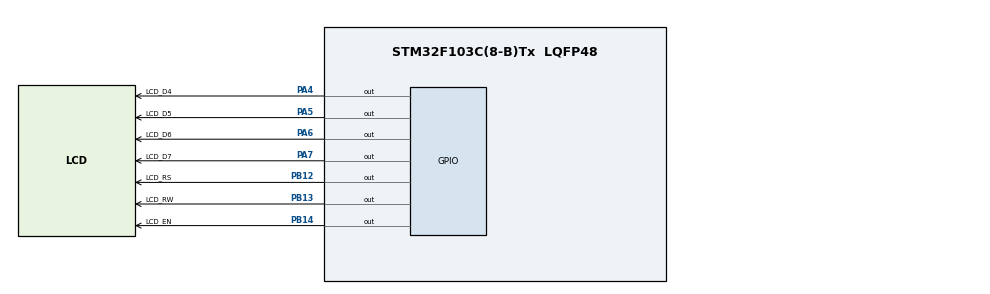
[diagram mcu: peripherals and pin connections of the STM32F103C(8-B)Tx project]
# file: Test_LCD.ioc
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Mcu.Family=STM32F1
PB14.GPIO_Label=LCD_EN
PA6.GPIO_Label=LCD_D6
PB13.GPIO_Label=LCD_RW
PB13.Signal=GPIO_Output
ProjectManager.StackSize=0x400
PA13.Signal=SYS_JTMS-SWDIO
ProjectManager.TargetToolchain=MDK-ARM V5
PB14.Signal=GPIO_Output
PA5.Signal=GPIO_Output
board=custom
PB12.GPIO_Label=LCD_RS
RCC.APB2Freq_Value=8000000
PA14.Mode=Serial_Wire
PA13.Mode=Serial_Wire
Mcu.Name=STM32F103C(8-B)Tx
PA4.Signal=GPIO_Output
Mcu.Package=LQFP48
PA6.Signal=GPIO_Output
PA7.GPIO_Label=LCD_D7
PA5.GPIO_Label=LCD_D5
PA14.Signal=SYS_JTCK-SWCLK
ProjectManager.HeapSize=0x200
NVIC.PriorityGroup=NVIC_PRIORITYGROUP_4
RCC.APB1Freq_Value=8000000
PA4.GPIO_Label=LCD_D4
PB12.Signal=GPIO_Output
PA7.Signal=GPIO_Output

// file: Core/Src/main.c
/* USER CODE BEGIN Header */
/**
  ******************************************************************************
  * @file           : main.c
  * @brief          : Main program body
  ******************************************************************************
  * @attention
  *
  * <h2><center>&copy; Copyright (c) 2021 STMicroelectronics.
  * All rights reserved.</center></h2>
  *
  * This software component is licensed by ST under BSD 3-Clause license,
  * the "License"; You may not use this file except in compliance with the
  * License. You may obtain a copy of the License at:
  *                        opensource.org/licenses/BSD-3-Clause
  *
  ******************************************************************************
  */
/* USER CODE END Header */
#include "main.h"

/* USER CODE BEGIN Includes */
#include "lcd.h"
/* USER CODE END Includes */

void SystemClock_Config(void);
static void MX_GPIO_Init(void);

int main(void)
{

  /* MCU Configuration--------------------------------------------------------*/

  /* Reset of all peripherals, Initializes the Flash interface and the Systick. */
  HAL_Init();

  /* Configure the system clock */
  SystemClock_Config();

  /* Initialize all configured peripherals */
  MX_GPIO_Init();

  /* Infinite loop */
  /* USER CODE BEGIN WHILE */
	Lcd_PortType ports[] = { LCD_D4_GPIO_Port,LCD_D5_GPIO_Port,LCD_D6_GPIO_Port,LCD_D7_GPIO_Port};
  Lcd_PinType pins[] = {LCD_D4_Pin,LCD_D5_Pin,LCD_D6_Pin,LCD_D7_Pin};
  Lcd_HandleTypeDef lcd = Lcd_create(ports, pins, LCD_RS_GPIO_Port, LCD_RS_Pin, LCD_EN_GPIO_Port, LCD_EN_Pin, LCD_4_BIT_MODE);

	Lcd_setCursor(&lcd,0,0);
  Lcd_putstr(&lcd,"Dang Loi 123");
  Lcd_setCursor(&lcd, 1,6);
  Lcd_putint(&lcd, 1998);

  while (1)
  {
    /* USER CODE END WHILE */

  }
}

void SystemClock_Config(void)
{
  RCC_OscInitTypeDef RCC_OscInitStruct = {0};
  RCC_ClkInitTypeDef RCC_ClkInitStruct = {0};

  /** Initializes the RCC Oscillators according to the specified parameters
  * in the RCC_OscInitTypeDef structure.
  */
  RCC_OscInitStruct.OscillatorType = RCC_OSCILLATORTYPE_HSI;
  RCC_OscInitStruct.HSIState = RCC_HSI_ON;
  RCC_OscInitStruct.HSICalibrationValue = RCC_HSICALIBRATION_DEFAULT;
  RCC_OscInitStruct.PLL.PLLState = RCC_PLL_NONE;
  if (HAL_RCC_OscConfig(&RCC_OscInitStruct) != HAL_OK)
  {
    Error_Handler();
  }
  /** Initializes the CPU, AHB and APB buses clocks
  */
  RCC_ClkInitStruct.ClockType = RCC_CLOCKTYPE_HCLK|RCC_CLOCKTYPE_SYSCLK
                              |RCC_CLOCKTYPE_PCLK1|RCC_CLOCKTYPE_PCLK2;
  RCC_ClkInitStruct.SYSCLKSource = RCC_SYSCLKSOURCE_HSI;
  RCC_ClkInitStruct.AHBCLKDivider = RCC_SYSCLK_DIV1;
  RCC_ClkInitStruct.APB1CLKDivider = RCC_HCLK_DIV1;
  RCC_ClkInitStruct.APB2CLKDivider = RCC_HCLK_DIV1;

  if (HAL_RCC_ClockConfig(&RCC_ClkInitStruct, FLASH_LATENCY_0) != HAL_OK)
  {
    Error_Handler();
  }
}

static void MX_GPIO_Init(void)
{
  GPIO_InitTypeDef GPIO_InitStruct = {0};

  /* GPIO Ports Clock Enable */
  __HAL_RCC_GPIOA_CLK_ENABLE();
  __HAL_RCC_GPIOB_CLK_ENABLE();

  /*Configure GPIO pin Output Level */
  HAL_GPIO_WritePin(GPIOA, LCD_D4_Pin|LCD_D5_Pin|LCD_D6_Pin|LCD_D7_Pin, GPIO_PIN_RESET);

  /*Configure GPIO pin Output Level */
  HAL_GPIO_WritePin(GPIOB, LCD_RS_Pin|LCD_RW_Pin|LCD_EN_Pin, GPIO_PIN_RESET);

  /*Configure GPIO pins : LCD_D4_Pin LCD_D5_Pin LCD_D6_Pin LCD_D7_Pin */
  GPIO_InitStruct.Pin = LCD_D4_Pin|LCD_D5_Pin|LCD_D6_Pin|LCD_D7_Pin;
  GPIO_InitStruct.Mode = GPIO_MODE_OUTPUT_PP;
  GPIO_InitStruct.Pull = GPIO_NOPULL;
  GPIO_InitStruct.Speed = GPIO_SPEED_FREQ_LOW;
  HAL_GPIO_Init(GPIOA, &GPIO_InitStruct);

  /*Configure GPIO pins : LCD_RS_Pin LCD_RW_Pin LCD_EN_Pin */
  GPIO_InitStruct.Pin = LCD_RS_Pin|LCD_RW_Pin|LCD_EN_Pin;
  GPIO_InitStruct.Mode = GPIO_MODE_OUTPUT_PP;
  GPIO_InitStruct.Pull = GPIO_NOPULL;
  GPIO_InitStruct.Speed = GPIO_SPEED_FREQ_LOW;
  HAL_GPIO_Init(GPIOB, &GPIO_InitStruct);

}

void Error_Handler(void)
{
}

/************************ (C) COPYRIGHT STMicroelectronics *****END OF FILE****/
